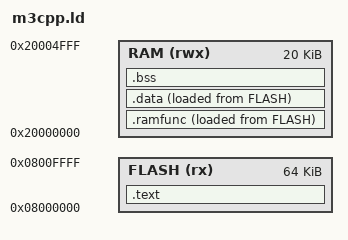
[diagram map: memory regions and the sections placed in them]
/* Gizmo, m3cpp build: m3.ld, and the C++ part's static constructors in .init_array (in flash; the
   startup calls them before main). */
ENTRY(Reset_Handler)
MEMORY
{
    FLASH (rx)  : ORIGIN = 0x08000000, LENGTH = 0x10000
    RAM   (rwx) : ORIGIN = 0x20000000, LENGTH = 0x5000
}
SECTIONS
{
    .text : {
        KEEP(*(.vectors))
        *(.text .text.*)
        *(.rodata .rodata.*)
        . = ALIGN(4);
        __init_array_start = .;
        KEEP(*(.init_array .init_array.*))
        __init_array_end = .;
    } > FLASH
    .ramfunc : {
        __ramfunc_start = .;
        *(.ramfunc .ramfunc.*)
        . = ALIGN(4);
        __ramfunc_end = .;
    } > RAM AT > FLASH
    __ramfunc_load = LOADADDR(.ramfunc);
    .data : {
        __data_start = .;
        *(.data .data.*)
        . = ALIGN(4);
        __data_end = .;
    } > RAM AT > FLASH
    __data_load = LOADADDR(.data);
    .bss (NOLOAD) : {
        __bss_start = .;
        *(.bss .bss.* COMMON)
        . = ALIGN(4);
        __bss_end = .;
    } > RAM
    __data_size = __data_end - __data_start;
    __ramfunc_size = __ramfunc_end - __ramfunc_start;
    __bss_size = __bss_end - __bss_start;
    __stack_top = ORIGIN(RAM) + LENGTH(RAM);
    __irq_stack_top = __stack_top - 0x800;
    _estack = __stack_top;
    /DISCARD/ : { *(.ARM.exidx*) *(.ARM.extab*) *(.comment) *(.note*) }
}
